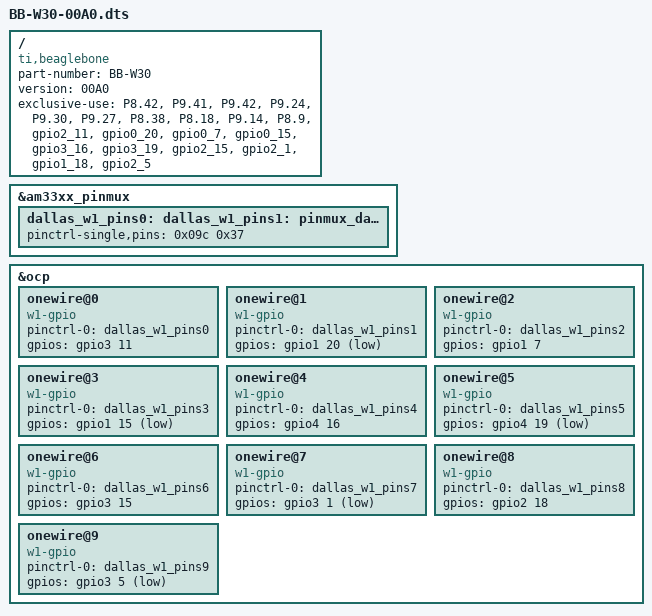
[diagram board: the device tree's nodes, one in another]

/dts-v1/;
/plugin/;

/ {
  compatible = "ti,beaglebone", "ti,beaglebone-black", "ti,beaglebone-green";

  part-number = "BB-W30";
  version = "00A0";

  /* state the resources this cape uses */
  exclusive-use =
    /* the pin header uses */
    "P8.42",
    "P9.41",
    "P9.42",
    "P9.24",
    "P9.30",
    "P9.27",
    "P8.38",
    "P8.18",
    "P9.14",
    "P8.9",

    /* the hardware IP uses */
    "gpio2_11",
    "gpio0_20",
    "gpio0_7",
    "gpio0_15",
    "gpio3_16",
    "gpio3_19",
    "gpio2_15",
    "gpio2_1",
    "gpio1_18",
    "gpio2_5";

  

  fragment@0 {
    target = <&am33xx_pinmux>;
    __overlay__ {
      dallas_w1_pins0: pinmux_dallas_w1_pins {
        pinctrl-single,pins = < 0x0b4 0x37 >;
      };
    };
  };

  fragment@1 {
    target = <&am33xx_pinmux>;
    __overlay__ {
      dallas_w1_pins1: pinmux_dallas_w1_pins {
        pinctrl-single,pins = < 0x1b4 0x37 >;
      };
    };
  };

  fragment@2 {
    target = <&am33xx_pinmux>;
    __overlay__ {
      dallas_w1_pins2: pinmux_dallas_w1_pins {
        pinctrl-single,pins = < 0x164 0x37 >;
      };
    };
  };

  fragment@3 {
    target = <&am33xx_pinmux>;
    __overlay__ {
      dallas_w1_pins3: pinmux_dallas_w1_pins {
        pinctrl-single,pins = < 0x184 0x37 >;
      };
    };
  };

  fragment@4 {
    target = <&am33xx_pinmux>;
    __overlay__ {
      dallas_w1_pins4: pinmux_dallas_w1_pins {
        pinctrl-single,pins = < 0x198 0x37 >;
      };
    };
  };

  fragment@5 {
    target = <&am33xx_pinmux>;
    __overlay__ {
      dallas_w1_pins5: pinmux_dallas_w1_pins {
        pinctrl-single,pins = < 0x1a4 0x37 >;
      };
    };
  };

  fragment@6 {
    target = <&am33xx_pinmux>;
    __overlay__ {
      dallas_w1_pins6: pinmux_dallas_w1_pins {
        pinctrl-single,pins = < 0x0c4 0x37 >;
      };
    };
  };

  fragment@7 {
    target = <&am33xx_pinmux>;
    __overlay__ {
      dallas_w1_pins7: pinmux_dallas_w1_pins {
        pinctrl-single,pins = < 0x08c 0x37 >;
      };
    };
  };

  fragment@8 {
    target = <&am33xx_pinmux>;
    __overlay__ {
      dallas_w1_pins8: pinmux_dallas_w1_pins {
        pinctrl-single,pins = < 0x048 0x37 >;
      };
    };
  };

  fragment@9 {
    target = <&am33xx_pinmux>;
    __overlay__ {
      dallas_w1_pins9: pinmux_dallas_w1_pins {
        pinctrl-single,pins = < 0x09c 0x37 >;
      };
    };
  };

  fragment@10 {
    target = <&ocp>;
    __overlay__ {

      onewire@0 {
        compatible = "w1-gpio";
        pinctrl-names   = "default";
        pinctrl-0       = <&dallas_w1_pins0>;
        status          = "okay";
        gpios = <&gpio3 11 0>;
      };

      onewire@1 {
        compatible = "w1-gpio";
        pinctrl-names   = "default";
        pinctrl-0       = <&dallas_w1_pins1>;
        status          = "okay";
        gpios = <&gpio1 20 1>;
      };

      onewire@2 {
        compatible = "w1-gpio";
        pinctrl-names   = "default";
        pinctrl-0       = <&dallas_w1_pins2>;
        status          = "okay";
        gpios = <&gpio1 7 2>;
      };

      onewire@3 {
        compatible = "w1-gpio";
        pinctrl-names   = "default";
        pinctrl-0       = <&dallas_w1_pins3>;
        status          = "okay";
        gpios = <&gpio1 15 3>;
      };

      onewire@4 {
        compatible = "w1-gpio";
        pinctrl-names   = "default";
        pinctrl-0       = <&dallas_w1_pins4>;
        status          = "okay";
        gpios = <&gpio4 16 4>;
      };

      onewire@5 {
        compatible = "w1-gpio";
        pinctrl-names   = "default";
        pinctrl-0       = <&dallas_w1_pins5>;
        status          = "okay";
        gpios = <&gpio4 19 5>;
      };

      onewire@6 {
        compatible = "w1-gpio";
        pinctrl-names   = "default";
        pinctrl-0       = <&dallas_w1_pins6>;
        status          = "okay";
        gpios = <&gpio3 15 6>;
      };

      onewire@7 {
        compatible = "w1-gpio";
        pinctrl-names   = "default";
        pinctrl-0       = <&dallas_w1_pins7>;
        status          = "okay";
        gpios = <&gpio3 1 7>;
      };

      onewire@8 {
        compatible = "w1-gpio";
        pinctrl-names   = "default";
        pinctrl-0       = <&dallas_w1_pins8>;
        status          = "okay";
        gpios = <&gpio2 18 8>;
      };

      onewire@9 {
        compatible = "w1-gpio";
        pinctrl-names   = "default";
        pinctrl-0       = <&dallas_w1_pins9>;
        status          = "okay";
        gpios = <&gpio3 5 9>;
      };
    };
  };
};
